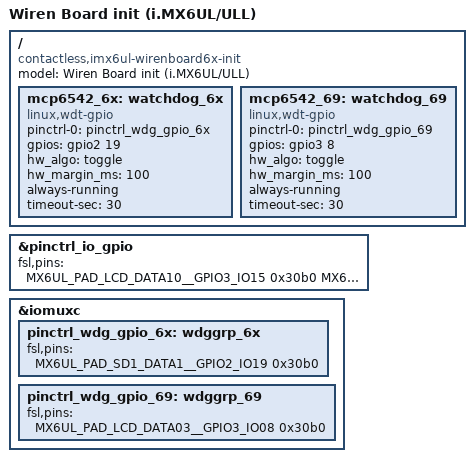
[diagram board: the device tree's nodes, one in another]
/dts-v1/;

#include "imx6ul-wirenboard61.dts"

/ {
	model = "Wiren Board init (i.MX6UL/ULL)";
	compatible = "contactless,imx6ul-wirenboard6x-init", "contactless,imx6ul-wirenboard690", "contactless,imx6ul-wirenboard680", "contactless,imx6ul-wirenboard670", "contactless,imx6ul-wirenboard660", "contactless,imx6ul-wirenboard65", "contactless,imx6ul-wirenboard61", "contactless,imx6ul-wirenboard60", "contactless,imx6ul-wirenboard-evk", "fsl,imx6ul-14x14-evk", "fsl,imx6ul";

	/delete-node/ mcp6542; // Defining 2 watchdog nodes: for wb6.x and wb 6.9.x

	mcp6542_6x: watchdog_6x {
		/* external watchdog timer using mcp6542 (wb 6.x < 6.9) */
		compatible = "linux,wdt-gpio";

		pinctrl-names = "default";
		pinctrl-0 = <&pinctrl_wdg_gpio_6x>;

		gpios = <&gpio2 19 0>;
		hw_algo = "toggle";
		hw_margin_ms = <100>;
		always-running;
		timeout-sec = <30>;
		status = "okay";
	};

	mcp6542_69: watchdog_69 {
		/* external watchdog timer using mcp6542 (wb 6.9+) */
		compatible = "linux,wdt-gpio";

		pinctrl-names = "default";
		pinctrl-0 = <&pinctrl_wdg_gpio_69>;

		gpios = <&gpio3 8 0>;
		hw_algo = "toggle";
		hw_margin_ms = <100>;
		always-running;
		timeout-sec = <30>;
		status = "okay";
	};
};


/* Releasing watchdog gpios for 6.x and 6.9.x:
	6.x - SD1_DATA1;
	6.9.x - LCD_DATA03 */

&pinctrl_io_gpio	{
	fsl,pins = <
		MX6UL_PAD_LCD_DATA10__GPIO3_IO15	0x30b0 /* FET1 */
		MX6UL_PAD_LCD_DATA11__GPIO3_IO16	0x30b0 /* FET2 */
		MX6UL_PAD_LCD_DATA12__GPIO3_IO17	0x30b0 /* FET3 */
		MX6UL_PAD_LCD_DATA13__GPIO3_IO18	0x30b0 /* FET4 */
		MX6UL_PAD_CSI_DATA03__GPIO4_IO24	0x30b0 /* RESET_SIM900 */
		MX6UL_PAD_LCD_DATA15__GPIO3_IO20	0x30b0 /* POWER_SIM900 */
		MX6UL_PAD_LCD_DATA14__GPIO3_IO19	0x30b0 /* STATUS SIM900 */
		MX6UL_PAD_LCD_DATA19__GPIO3_IO24	0x30b0 /* SIM select */
		MX6UL_PAD_UART1_CTS_B__GPIO1_IO18	0xf0b0 /* Battery STAT1, 22K Ohm pulled up */
		MX6UL_PAD_UART1_RTS_B__GPIO1_IO19	0xf0b0 /* Battery STAT2, 22K Ohm pulled up */
		MX6UL_PAD_JTAG_TDO__CCM_CLKO2	0xb0 /* 24MHz clock output */
		MX6UL_PAD_UART3_RTS_B__GPIO1_IO27	0x30b0 /* 5V enable */
		MX6UL_PAD_LCD_DATA04__GPIO3_IO09	0x30b0 /* V_OUT_ON */
		MX6UL_PAD_CSI_DATA02__GPIO4_IO23	0x70b0 /* RS-485-1 failsafe bias, pulled up */

		MX6UL_PAD_NAND_CE0_B__GPIO4_IO13 	0x30b0 /* IN1 */
		MX6UL_PAD_NAND_CLE__GPIO4_IO15 	0x30b0 /* IN2 */
		MX6UL_PAD_NAND_CE1_B__GPIO4_IO14 	0x30b0 /* IN3 */
		MX6UL_PAD_GPIO1_IO00__GPIO1_IO00 	0x30b0 /* IN4 */

		MX6UL_PAD_JTAG_MOD__GPIO1_IO10		0x80000000 /* SPDIF_OUT connected to MODULE 2 TX PIN via 3K, must be high when i2c*/
	>;
};


&iomuxc {
	/delete-node/ pinctrl_wdg_gpio;

	pinctrl_wdg_gpio_6x: wdggrp_6x {
		fsl,pins = <
			MX6UL_PAD_SD1_DATA1__GPIO2_IO19	0x30b0 /* watchdog toggle out (wb 6.x < 6.9) */
		>;
	};

	pinctrl_wdg_gpio_69: wdggrp_69 {
		fsl,pins = <
			MX6UL_PAD_LCD_DATA03__GPIO3_IO08	0x30b0 /* watchdog toggle out (wb 6.9) */
		>;
	};
};
